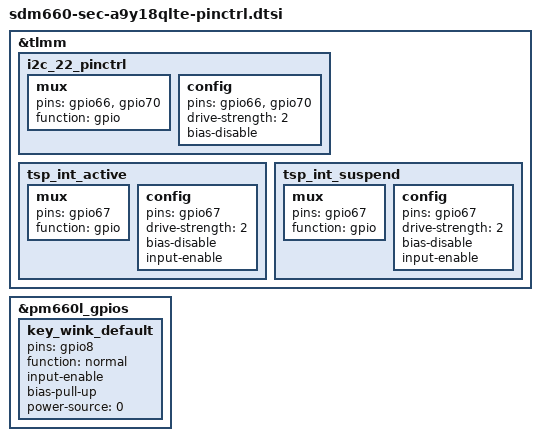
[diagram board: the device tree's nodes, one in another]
// SPDX-License-Identifier: GPL-2.0-only
/*
 * a9y18qlte pin settings, from sdm660-sec-a9y18qlte-eur-pinctrl-r06.dtsi
 * on 4.4. Groups are added here as their drivers are ported.
 */

&tlmm {
	i2c_22_pinctrl: i2c_22_pinctrl {
		mux {
			pins = "gpio66",	/* OCTA_PMIC_SDA_1P8 */
			       "gpio70";	/* OCTA_PMIC_SCL_1P8 */
			function = "gpio";
		};
		config {
			pins = "gpio66", "gpio70";
			drive-strength = <2>;
			bias-disable;
		};
	};
};

&tlmm {
	tsp_int_active: tsp_int_active {
		mux {
			pins = "gpio67";
			function = "gpio";
		};
		config {
			pins = "gpio67";
			drive-strength = <2>;
			bias-disable;
			input-enable;
		};
	};

	tsp_int_suspend: tsp_int_suspend {
		mux {
			pins = "gpio67";
			function = "gpio";
		};
		config {
			pins = "gpio67";
			drive-strength = <2>;
			bias-disable;
			input-enable;
		};
	};
};

&pm660l_gpios {
	/* GPIO 8, Bixby key */
	key_wink_default: key_wink_default {
		pins = "gpio8";
		function = "normal";
		input-enable;
		bias-pull-up;
		power-source = <0>;
	};
};
